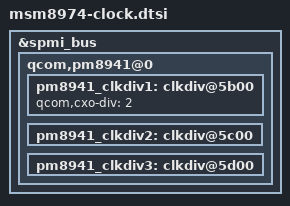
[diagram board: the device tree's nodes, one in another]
/* Copyright (c) 2012, The Linux Foundation. All rights reserved.
 *
 * This program is free software; you can redistribute it and/or modify
 * it under the terms of the GNU General Public License version 2 and
 * only version 2 as published by the Free Software Foundation.
 *
 * This program is distributed in the hope that it will be useful,
 * but WITHOUT ANY WARRANTY; without even the implied warranty of
 * MERCHANTABILITY or FITNESS FOR A PARTICULAR PURPOSE.  See the
 * GNU General Public License for more details.
 */

&spmi_bus {

	qcom,pm8941@0 {

		pm8941_clkdiv1: clkdiv@5b00 {
			qcom,cxo-div = <2>;
		};

		pm8941_clkdiv2: clkdiv@5c00 {
		};

		pm8941_clkdiv3: clkdiv@5d00 {
		};
	};
};
